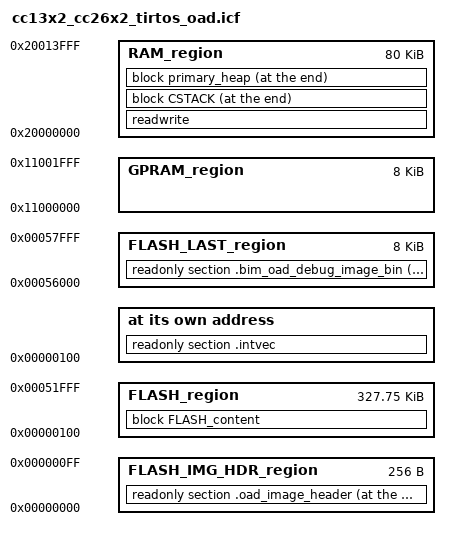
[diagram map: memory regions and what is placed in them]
/*
 * Copyright (c) 2017-2020, Texas Instruments Incorporated
 * All rights reserved.
 *
 * Redistribution and use in source and binary forms, with or without
 * modification, are permitted provided that the following conditions
 * are met:
 *
 * *  Redistributions of source code must retain the above copyright
 *    notice, this list of conditions and the following disclaimer.
 *
 * *  Redistributions in binary form must reproduce the above copyright
 *    notice, this list of conditions and the following disclaimer in the
 *    documentation and/or other materials provided with the distribution.
 *
 * *  Neither the name of Texas Instruments Incorporated nor the names of
 *    its contributors may be used to endorse or promote products derived
 *    from this software without specific prior written permission.
 *
 * THIS SOFTWARE IS PROVIDED BY THE COPYRIGHT HOLDERS AND CONTRIBUTORS "AS IS"
 * AND ANY EXPRESS OR IMPLIED WARRANTIES, INCLUDING, BUT NOT LIMITED TO,
 * THE IMPLIED WARRANTIES OF MERCHANTABILITY AND FITNESS FOR A PARTICULAR
 * PURPOSE ARE DISCLAIMED. IN NO EVENT SHALL THE COPYRIGHT OWNER OR
 * CONTRIBUTORS BE LIABLE FOR ANY DIRECT, INDIRECT, INCIDENTAL, SPECIAL,
 * EXEMPLARY, OR CONSEQUENTIAL DAMAGES (INCLUDING, BUT NOT LIMITED TO,
 * PROCUREMENT OF SUBSTITUTE GOODS OR SERVICES; LOSS OF USE, DATA, OR PROFITS;
 * OR BUSINESS INTERRUPTION) HOWEVER CAUSED AND ON ANY THEORY OF LIABILITY,
 * WHETHER IN CONTRACT, STRICT LIABILITY, OR TORT (INCLUDING NEGLIGENCE OR
 * OTHERWISE) ARISING IN ANY WAY OUT OF THE USE OF THIS SOFTWARE,
 * EVEN IF ADVISED OF THE POSSIBILITY OF SUCH DAMAGE.
 */

/*-Memory Regions-*/
define symbol OAD_HDR_start__ = 0x00000000;
define symbol OAD_HDR_end__   = 0x000000FF;
define symbol ROM_start__     = 0x00000100;
define symbol ROM_end__       = 0x00051FFF;
define symbol NVS_start__     = 0x00052000;
define symbol NVS_end__       = 0x00055FFF;
define symbol BIM_start__     = 0x00056000;
define symbol BIM_end__       = 0x00057FFF;

define symbol RAM_start__     = 0x20000000;
define symbol RAM_end__       = 0x20013FFF;
define symbol GPRAM_start__   = 0x11000000;
define symbol GPRAM_end__     = 0x11001FFF;

/* Define a memory region that covers the entire 4 GB addressable space */
define memory mem with size = 4G;

/* OAD Image Header */
define region FLASH_IMG_HDR_region = mem:[from OAD_HDR_start__ to OAD_HDR_end__];

/* Define a region for the on-chip flash */
define region FLASH_region = mem:[from ROM_start__ to ROM_end__];

/* Define a region for the on-chip flash used for NV storage */
define region FLASH_NV_region = mem:[from NVS_end__ to NVS_end__];

/* Define a region for the last flash page */
define region FLASH_LAST_region = mem:[from BIM_start__ to BIM_end__];

/* Internal RAM for data used by application */
define region RAM_region = mem:[from RAM_start__ to RAM_end__];

/* Define a region for the on-chip GPRAM */
define region GPRAM_region     = mem:[from GPRAM_start__ to GPRAM_end__];

/* Place the interrupt vectors at the start of flash */
place at address mem:ROM_start__ { readonly section .intvec };
keep { section .intvec};

/* Place the default bim at the end of flash */
place at end of FLASH_LAST_region { readonly section .bim_oad_debug_image_bin };
keep { section .bim_oad_debug_image_bin };

/* Flash OAD Image Header */
place at start of FLASH_IMG_HDR_region { readonly section .oad_image_header };
keep { readonly section .oad_image_header };

/* Place remaining 'read only' in Flash */
define block FLASH_content with fixed order
{
    readonly,
    readonly section .flash_end_address,
};
keep { section flash_end_address };
place in FLASH_region { block FLASH_content };

/* Place all read/write items into RAM */
place in RAM_region   { readwrite };
initialize by copy { readwrite };

/*
 * Define CSTACK block to contain .stack section. This enables the IAR IDE
 * to properly show the stack content during debug. Place stack at end of
 * retention RAM, do not initialize (initializing the stack will destroy the
 * return address from the initialization code, causing the processor to branch
 * to zero and fault)
 */
define symbol STACKSIZE = 1024;
define block CSTACK with alignment = 8, size = STACKSIZE { section .stack };
place at end of RAM_region { block CSTACK };
do not initialize { section .stack, section .noinit};

/* Export stack top symbol. Used by startup file */
define exported symbol STACK_TOP = RAM_end__ + 1;

/* HeapMem Primary Heap configuration */
define symbol HEAPSIZE = 0x1000;
define block primary_heap with alignment = 8, size = HEAPSIZE { };

/* Place heap just before CSTACK */
place at end of RAM_region { block primary_heap };

/* Define buffer start and end symbols for HeapMem Primary Heap */
define exported symbol __primary_heap_end__ = end(RAM_region) - STACKSIZE;
define exported symbol __primary_heap_start__ = __primary_heap_end__ - HEAPSIZE;

/*
 * The USE_TIRTOS_ROM symbol is defined internally in the build flow (using
 * --config_def USE_TIRTOS_ROM=1) for TI-RTOS applications whose app.cfg file
 * specifies to use the ROM.
 */
if (isdefinedsymbol(USE_TIRTOS_ROM)) {
    include "TIRTOS_ROM.icf";
}
